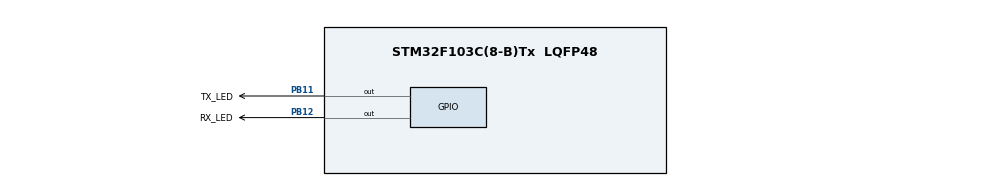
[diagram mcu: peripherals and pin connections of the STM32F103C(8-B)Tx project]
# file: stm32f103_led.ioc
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Mcu.Family=STM32F1
Mcu.Name=STM32F103C(8-B)Tx
Mcu.Package=LQFP48
NVIC.PriorityGroup=NVIC_PRIORITYGROUP_4
PA13.Mode=JTAG_4_pins
PA13.Signal=SYS_JTMS-SWDIO
PA14.Mode=JTAG_4_pins
PA14.Signal=SYS_JTCK-SWCLK
PA15.Mode=JTAG_4_pins
PA15.Signal=SYS_JTDI
PB11.GPIO_Label=TX_LED
PB11.Signal=GPIO_Output
PB12.GPIO_Label=RX_LED
PB12.Signal=GPIO_Output
PB3.Mode=JTAG_4_pins
PB3.Signal=SYS_JTDO-TRACESWO
PD0-OSC_IN.Mode=HSE-External-Oscillator
PD0-OSC_IN.Signal=RCC_OSC_IN
PD1-OSC_OUT.Mode=HSE-External-Oscillator
PD1-OSC_OUT.Signal=RCC_OSC_OUT
ProjectManager.HeapSize=0x200
ProjectManager.StackSize=0x400
ProjectManager.TargetToolchain=Makefile
RCC.AHBFreq_Value=72000000
RCC.APB1CLKDivider=RCC_HCLK_DIV2
RCC.APB1Freq_Value=36000000
RCC.APB1TimFreq_Value=72000000
RCC.APB2Freq_Value=72000000
RCC.APB2TimFreq_Value=72000000
RCC.HCLKFreq_Value=72000000
RCC.PLLMUL=RCC_PLL_MUL9
RCC.PLLSourceVirtual=RCC_PLLSOURCE_HSE
RCC.SYSCLKFreq_VALUE=72000000
RCC.SYSCLKSource=RCC_SYSCLKSOURCE_PLLCLK
RCC.USBFreq_Value=72000000
board=custom

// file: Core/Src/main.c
/* USER CODE BEGIN Header */
/**
  ******************************************************************************
  * @file           : main.c
  * @brief          : Main program body
  ******************************************************************************
  * @attention
  *
  * <h2><center>&copy; Copyright (c) 2019 STMicroelectronics.
  * All rights reserved.</center></h2>
  *
  * This software component is licensed by ST under BSD 3-Clause license,
  * the "License"; You may not use this file except in compliance with the
  * License. You may obtain a copy of the License at:
  *                        opensource.org/licenses/BSD-3-Clause
  *
  ******************************************************************************
  */
/* USER CODE END Header */

#include "main.h"
#include "gpio.h"

void SystemClock_Config(void);

int main(void)
{

  /* MCU Configuration--------------------------------------------------------*/

  /* Reset of all peripherals, Initializes the Flash interface and the Systick. */

  LL_APB2_GRP1_EnableClock(LL_APB2_GRP1_PERIPH_AFIO);
  LL_APB1_GRP1_EnableClock(LL_APB1_GRP1_PERIPH_PWR);

  NVIC_SetPriorityGrouping(NVIC_PRIORITYGROUP_4);

  /* System interrupt init*/

  /** NONJTRST: Full SWJ (JTAG-DP + SW-DP) but without NJTRST
  */
  LL_GPIO_AF_Remap_SWJ_NONJTRST();

  /* Configure the system clock */
  SystemClock_Config();

  /* Initialize all configured peripherals */
  MX_GPIO_Init();
  /* USER CODE BEGIN 2 */
  LL_GPIO_SetOutputPin(RX_LED_GPIO_Port, RX_LED_Pin);
  LL_GPIO_ResetOutputPin(TX_LED_GPIO_Port, TX_LED_Pin);
  /* USER CODE END 2 */

  /* Infinite loop */
  while (1)
  {
    LL_GPIO_TogglePin(RX_LED_GPIO_Port, RX_LED_Pin);
    LL_GPIO_TogglePin(TX_LED_GPIO_Port, TX_LED_Pin);
    LL_mDelay(200);
  }
}

void SystemClock_Config(void)
{
  LL_FLASH_SetLatency(LL_FLASH_LATENCY_2);

   if(LL_FLASH_GetLatency() != LL_FLASH_LATENCY_2)
  {
    Error_Handler();
  }
  LL_RCC_HSE_Enable();

   /* Wait till HSE is ready */
  while(LL_RCC_HSE_IsReady() != 1)
  {

  }
  LL_RCC_PLL_ConfigDomain_SYS(LL_RCC_PLLSOURCE_HSE_DIV_1, LL_RCC_PLL_MUL_9);
  LL_RCC_PLL_Enable();

   /* Wait till PLL is ready */
  while(LL_RCC_PLL_IsReady() != 1)
  {

  }
  LL_RCC_SetAHBPrescaler(LL_RCC_SYSCLK_DIV_1);
  LL_RCC_SetAPB1Prescaler(LL_RCC_APB1_DIV_2);
  LL_RCC_SetAPB2Prescaler(LL_RCC_APB2_DIV_1);
  LL_RCC_SetSysClkSource(LL_RCC_SYS_CLKSOURCE_PLL);

   /* Wait till System clock is ready */
  while(LL_RCC_GetSysClkSource() != LL_RCC_SYS_CLKSOURCE_STATUS_PLL)
  {

  }
  LL_Init1msTick(72000000);
  LL_SYSTICK_SetClkSource(LL_SYSTICK_CLKSOURCE_HCLK);
  LL_SetSystemCoreClock(72000000);
}

void Error_Handler(void)
{
}

/************************ (C) COPYRIGHT STMicroelectronics *****END OF FILE****/
